# f29h85x_hsm_sha_s_regs register map
Vendor: Texas Instruments
Peripheral module from a debugger description file (folder HSM).
Registers are 32-bit, read-write, no defined reset value unless marked. A register's access mark holds for its fields unless they carry their own. Offsets are as the file gives them; lines under a group give offsets from that group; [hi:lo] are bit positions; {n}, {i} and the like mark numbered series; 'fields as' and 'values as' point back to an identical list; <NAME> marks a mode.

## HSM_SHA_S — HSM SHA S Registers
0x00 S_ODIGEST_A
  [31:0] DATA
0x04 S_ODIGEST_B
  [31:0] DATA
0x08 S_ODIGEST_C
  [31:0] DATA
0x0C S_ODIGEST_D
  [31:0] DATA
0x10 S_ODIGEST_E
  [31:0] DATA
0x14 S_ODIGEST_F
  [31:0] DATA
0x18 S_ODIGEST_G
  [31:0] DATA
0x1C S_ODIGEST_H
  [31:0] DATA
0x20 S_IDIGEST_A
  [31:0] DATA
0x24 S_IDIGEST_B
  [31:0] DATA
0x28 S_IDIGEST_C
  [31:0] DATA
0x2C S_IDIGEST_D
  [31:0] DATA
0x30 S_IDIGEST_E
  [31:0] DATA
0x34 S_IDIGEST_F
  [31:0] DATA
0x38 S_IDIGEST_G
  [31:0] DATA
0x3C S_IDIGEST_H
  [31:0] DATA
0x40 S_DIGEST_COUNT
  [31:0] DATA
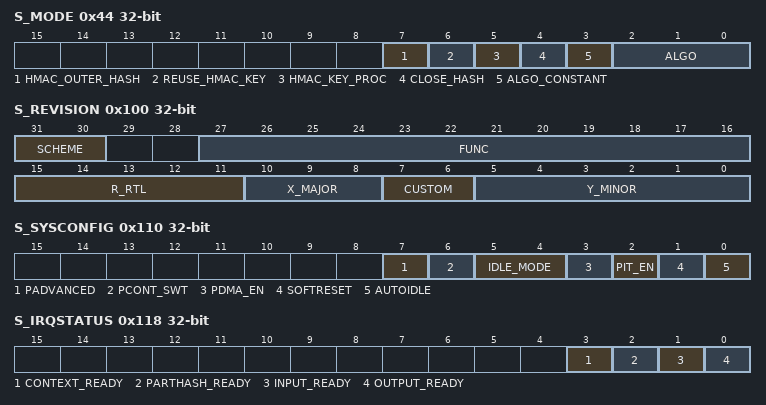
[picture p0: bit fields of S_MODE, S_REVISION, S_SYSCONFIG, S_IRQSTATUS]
0x44 S_MODE access per field
  [7] HMAC_OUTER_HASH rw, [6] REUSE_HMAC_KEY rw, [5] HMAC_KEY_PROC rw, [4] CLOSE_HASH rw, [3] ALGO_CONSTANT rw, [2:0] ALGO rw
0x48 S_LENGTH
  [31:0] DATA
{0x80+4i} S_DATA{i}_IN (i=0..31)
  [31:0] DATA{i}_IN
0x100 S_REVISION ro
  [31:30] SCHEME, [27:16] FUNC, [15:11] R_RTL, [10:8] X_MAJOR, [7:6] CUSTOM, [5:0] Y_MINOR
0x110 S_SYSCONFIG access per field
  [7] PADVANCED rw, [6] PCONT_SWT rw, [5:4] IDLE_MODE rw, [3] PDMA_EN rw, [2] PIT_EN rw, [1] SOFTRESET rw, [0] AUTOIDLE rw
0x114 S_SYSSTATUS ro
  [0] RESETDONE
0x118 S_IRQSTATUS ro
  [3] CONTEXT_READY, [2] PARTHASH_READY, [1] INPUT_READY, [0] OUTPUT_READY
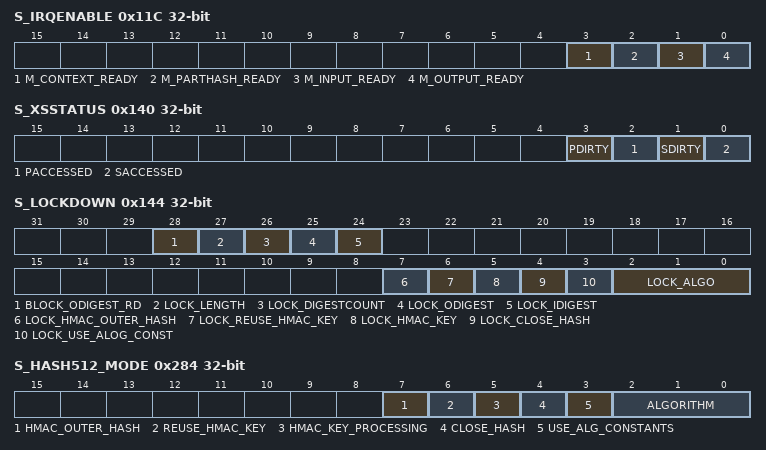
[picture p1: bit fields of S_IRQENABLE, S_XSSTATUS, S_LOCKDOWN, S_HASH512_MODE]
0x11C S_IRQENABLE access per field
  [3] M_CONTEXT_READY rw, [2] M_PARTHASH_READY rw, [1] M_INPUT_READY rw, [0] M_OUTPUT_READY rw
0x140 S_XSSTATUS access per field
  [3] PDIRTY rw, [2] PACCESSED rw, [1] SDIRTY rw, [0] SACCESSED rw
0x144 S_LOCKDOWN access per field
  [28] BLOCK_ODIGEST_RD rw, [27] LOCK_LENGTH rw, [26] LOCK_DIGESTCOUNT rw, [25] LOCK_ODIGEST rw, [24] LOCK_IDIGEST rw, [7] LOCK_HMAC_OUTER_HASH rw, [6] LOCK_REUSE_HMAC_KEY rw, [5] LOCK_HMAC_KEY rw, [4] LOCK_CLOSE_HASH rw, [3] LOCK_USE_ALOG_CONST rw, [2:0] LOCK_ALGO rw
0x200 S_HASH512_ODIGEST_A
  [31:0] ODIGEST_A
0x204 S_HASH512_ODIGEST_B
  [31:0] ODIGEST_B
0x208 S_HASH512_ODIGEST_C
  [31:0] ODIGEST_C
0x20C S_HASH512_ODIGEST_D
  [31:0] ODIGEST_D
0x210 S_HASH512_ODIGEST_E
  [31:0] ODIGEST_E
0x214 S_HASH512_ODIGEST_F
  [31:0] ODIGEST_F
0x218 S_HASH512_ODIGEST_G
  [31:0] ODIGEST_G
0x21C S_HASH512_ODIGEST_H
  [31:0] ODIGEST_H
0x220 S_HASH512_ODIGEST_I
  [31:0] ODIGEST_I
0x224 S_HASH512_ODIGEST_J
  [31:0] ODIGEST_J
0x228 S_HASH512_ODIGEST_K
  [31:0] ODIGEST_K
0x22C S_HASH512_ODIGEST_L
  [31:0] ODIGEST_L
0x230 S_HASH512_ODIGEST_M
  [31:0] ODIGEST_M
0x234 S_HASH512_ODIGEST_N
  [31:0] ODIGEST_N
0x238 S_HASH512_ODIGEST_O
  [31:0] ODIGEST_O
0x23C S_HASH512_ODIGEST_P
  [31:0] ODIGEST_P
0x240 S_HASH512_IDIGEST_A
  [31:0] IDIGEST_A
0x244 S_HASH512_IDIGEST_B
  [31:0] IDIGEST_B
0x248 S_HASH512_IDIGEST_C
  [31:0] IDIGEST_C
0x24C S_HASH512_IDIGEST_D
  [31:0] IDIGEST_D
0x250 S_HASH512_IDIGEST_E
  [31:0] IDIGEST_E
0x254 S_HASH512_IDIGEST_F
  [31:0] IDIGEST_F
0x258 S_HASH512_IDIGEST_G
  [31:0] IDIGEST_G
0x25C S_HASH512_IDIGEST_H
  [31:0] IDIGEST_H
0x260 S_HASH512_IDIGEST_I
  [31:0] IDIGEST_I
0x264 S_HASH512_IDIGEST_J
  [31:0] IDIGEST_J
0x268 S_HASH512_IDIGEST_K
  [31:0] IDIGEST_K
0x26C S_HASH512_IDIGEST_L
  [31:0] IDIGEST_L
0x270 S_HASH512_IDIGEST_M
  [31:0] IDIGEST_M
0x274 S_HASH512_IDIGEST_N
  [31:0] IDIGEST_N
0x278 S_HASH512_IDIGEST_O
  [31:0] IDIGEST_O
0x27C S_HASH512_IDIGEST_P
  [31:0] IDIGEST_P
0x280 S_HASH512_DIGEST_COUNT
  [31:0] DIGEST_COUNT
0x284 S_HASH512_MODE access per field
  [7] HMAC_OUTER_HASH rw, [6] REUSE_HMAC_KEY rw, [5] HMAC_KEY_PROCESSING rw, [4] CLOSE_HASH rw, [3] USE_ALG_CONSTANTS rw, [2:0] ALGORITHM rw
0x288 S_HASH512_LENGTH
